AUTOSAR XML (schema 4-0-3)
package /ComponentTypes
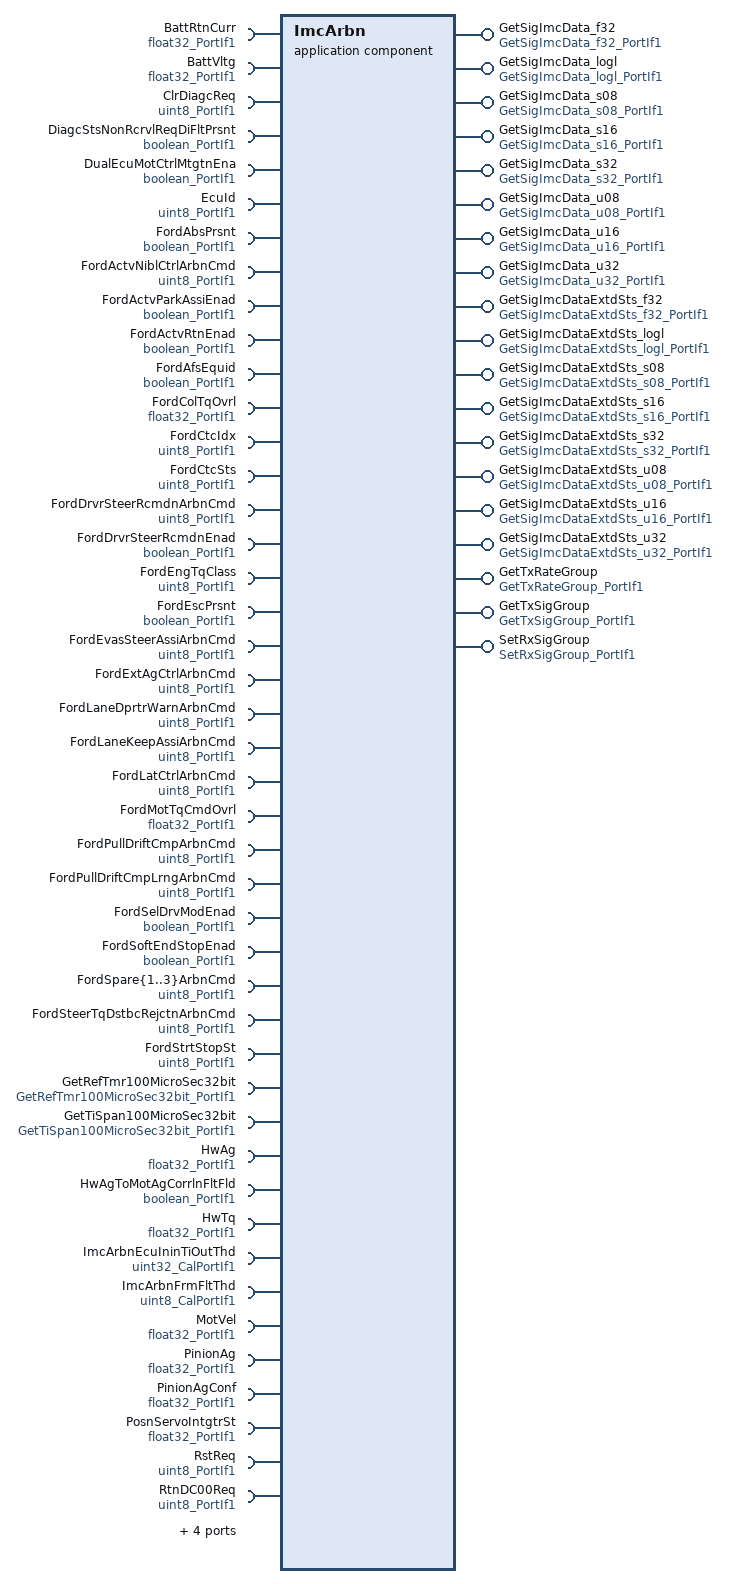
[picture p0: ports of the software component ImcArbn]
  application sw component type ImcArbn
    19 x provide port, all with server-com-spec{operation=Oper, queue-length=1}:
      GetSigImcData_f32: provided-interface=GetSigImcData_f32_PortIf1
      GetSigImcData_logl: provided-interface=GetSigImcData_logl_PortIf1
      GetSigImcData_s08: provided-interface=GetSigImcData_s08_PortIf1
      GetSigImcData_s16: provided-interface=GetSigImcData_s16_PortIf1
      GetSigImcData_s32: provided-interface=GetSigImcData_s32_PortIf1
      GetSigImcData_u08: provided-interface=GetSigImcData_u08_PortIf1
      GetSigImcData_u16: provided-interface=GetSigImcData_u16_PortIf1
      GetSigImcData_u32: provided-interface=GetSigImcData_u32_PortIf1
      GetSigImcDataExtdSts_f32: provided-interface=GetSigImcDataExtdSts_f32_PortIf1
      GetSigImcDataExtdSts_logl: provided-interface=GetSigImcDataExtdSts_logl_PortIf1
      GetSigImcDataExtdSts_s08: provided-interface=GetSigImcDataExtdSts_s08_PortIf1
      GetSigImcDataExtdSts_s16: provided-interface=GetSigImcDataExtdSts_s16_PortIf1
      GetSigImcDataExtdSts_s32: provided-interface=GetSigImcDataExtdSts_s32_PortIf1
      GetSigImcDataExtdSts_u08: provided-interface=GetSigImcDataExtdSts_u08_PortIf1
      GetSigImcDataExtdSts_u16: provided-interface=GetSigImcDataExtdSts_u16_PortIf1
      GetSigImcDataExtdSts_u32: provided-interface=GetSigImcDataExtdSts_u32_PortIf1
      GetTxRateGroup: provided-interface=GetTxRateGroup_PortIf1
      GetTxSigGroup: provided-interface=GetTxSigGroup_PortIf1
      SetRxSigGroup: provided-interface=SetRxSigGroup_PortIf1
    50 x require port:
      BattRtnCurr: nonqueued-receiver-com-spec{data-element=Val, filter=data-filter-type=ALWAYS}, required-interface=float32_PortIf1
      BattVltg: nonqueued-receiver-com-spec{data-element=Val, filter=data-filter-type=ALWAYS, init-value=6}, required-interface=float32_PortIf1
      ClrDiagcReq: nonqueued-receiver-com-spec{data-element=Val, filter=data-filter-type=ALWAYS, init-value=0}, required-interface=uint8_PortIf1
      DiagcStsNonRcrvlReqDiFltPrsnt: nonqueued-receiver-com-spec{data-element=Logl, filter=data-filter-type=ALWAYS, init-value=0}, required-interface=boolean_PortIf1
      DualEcuMotCtrlMtgtnEna: nonqueued-receiver-com-spec{data-element=Logl, filter=data-filter-type=ALWAYS, init-value=0}, required-interface=boolean_PortIf1
      EcuId: nonqueued-receiver-com-spec{data-element=Val, filter=data-filter-type=ALWAYS, init-value=0}, required-interface=uint8_PortIf1
      FordAbsPrsnt: nonqueued-receiver-com-spec{data-element=Logl, filter=data-filter-type=ALWAYS, init-value=0}, required-interface=boolean_PortIf1
      FordActvNiblCtrlArbnCmd: nonqueued-receiver-com-spec{data-element=Val, filter=data-filter-type=ALWAYS, init-value=0}, required-interface=uint8_PortIf1
      FordActvParkAssiEnad: nonqueued-receiver-com-spec{data-element=Logl, filter=data-filter-type=ALWAYS, init-value=0}, required-interface=boolean_PortIf1
      FordActvRtnEnad: nonqueued-receiver-com-spec{data-element=Logl, filter=data-filter-type=ALWAYS, init-value=1}, required-interface=boolean_PortIf1
      FordAfsEquid: nonqueued-receiver-com-spec{data-element=Logl, filter=data-filter-type=ALWAYS, init-value=0}, required-interface=boolean_PortIf1
      FordColTqOvrl: nonqueued-receiver-com-spec{data-element=Val, filter=data-filter-type=ALWAYS, init-value=0}, required-interface=float32_PortIf1
      FordCtcIdx: nonqueued-receiver-com-spec{data-element=Val, filter=data-filter-type=ALWAYS, init-value=0}, required-interface=uint8_PortIf1
      FordCtcSts: nonqueued-receiver-com-spec{data-element=Val, filter=data-filter-type=ALWAYS, init-value=0}, required-interface=uint8_PortIf1
      FordDrvrSteerRcmdnArbnCmd: nonqueued-receiver-com-spec{data-element=Val, filter=data-filter-type=ALWAYS, init-value=0}, required-interface=uint8_PortIf1
      FordDrvrSteerRcmdnEnad: nonqueued-receiver-com-spec{data-element=Logl, filter=data-filter-type=ALWAYS, init-value=0}, required-interface=boolean_PortIf1
      FordEngTqClass: nonqueued-receiver-com-spec{data-element=Val, filter=data-filter-type=ALWAYS, init-value=2}, required-interface=uint8_PortIf1
      FordEscPrsnt: nonqueued-receiver-com-spec{data-element=Logl, filter=data-filter-type=ALWAYS, init-value=0}, required-interface=boolean_PortIf1
      FordEvasSteerAssiArbnCmd: nonqueued-receiver-com-spec{data-element=Val, filter=data-filter-type=ALWAYS, init-value=0}, required-interface=uint8_PortIf1
      FordExtAgCtrlArbnCmd: nonqueued-receiver-com-spec{data-element=Val, filter=data-filter-type=ALWAYS, init-value=0}, required-interface=uint8_PortIf1
      FordLaneDprtrWarnArbnCmd: nonqueued-receiver-com-spec{data-element=Val, filter=data-filter-type=ALWAYS, init-value=0}, required-interface=uint8_PortIf1
      FordLaneKeepAssiArbnCmd: nonqueued-receiver-com-spec{data-element=Val, filter=data-filter-type=ALWAYS, init-value=0}, required-interface=uint8_PortIf1
      FordLatCtrlArbnCmd: nonqueued-receiver-com-spec{data-element=Val, filter=data-filter-type=ALWAYS, init-value=0}, required-interface=uint8_PortIf1
      FordMotTqCmdOvrl: nonqueued-receiver-com-spec{data-element=Val, filter=data-filter-type=ALWAYS, init-value=0}, required-interface=float32_PortIf1
      FordPullDriftCmpArbnCmd: nonqueued-receiver-com-spec{data-element=Val, filter=data-filter-type=ALWAYS, init-value=0}, required-interface=uint8_PortIf1
      FordPullDriftCmpLrngArbnCmd: nonqueued-receiver-com-spec{data-element=Val, filter=data-filter-type=ALWAYS, init-value=0}, required-interface=uint8_PortIf1
      FordSelDrvModEnad: nonqueued-receiver-com-spec{data-element=Logl, filter=data-filter-type=ALWAYS, init-value=0}, required-interface=boolean_PortIf1
      FordSoftEndStopEnad: nonqueued-receiver-com-spec{data-element=Logl, filter=data-filter-type=ALWAYS, init-value=0}, required-interface=boolean_PortIf1
      FordSpare{1..3}ArbnCmd: nonqueued-receiver-com-spec{data-element=Val, filter=data-filter-type=ALWAYS, init-value=0}, required-interface=uint8_PortIf1
      FordSteerTqDstbcRejctnArbnCmd: nonqueued-receiver-com-spec{data-element=Val, filter=data-filter-type=ALWAYS, init-value=0}, required-interface=uint8_PortIf1
      FordStrtStopSt: nonqueued-receiver-com-spec{data-element=Val, filter=data-filter-type=ALWAYS, init-value=0}, required-interface=uint8_PortIf1
      GetRefTmr100MicroSec32bit: client-com-spec=Oper, required-interface=GetRefTmr100MicroSec32bit_PortIf1
      GetTiSpan100MicroSec32bit: client-com-spec=Oper, required-interface=GetTiSpan100MicroSec32bit_PortIf1
      HwAg: nonqueued-receiver-com-spec{data-element=Val, filter=data-filter-type=ALWAYS, init-value=0}, required-interface=float32_PortIf1
      HwAgToMotAgCorrlnFltFld: nonqueued-receiver-com-spec{data-element=Logl, filter=data-filter-type=ALWAYS, init-value=0}, required-interface=boolean_PortIf1
      HwTq: nonqueued-receiver-com-spec{data-element=Val, filter=data-filter-type=ALWAYS, init-value=0}, required-interface=float32_PortIf1
      ImcArbnEcuIninTiOutThd: parameter-require-com-spec{init-value=500, parameter=Val}, required-interface=uint32_CalPortIf1
      ImcArbnFrmFltThd: parameter-require-com-spec{init-value=10, parameter=Val}, required-interface=uint8_CalPortIf1
      MotVel: nonqueued-receiver-com-spec{data-element=Val, filter=data-filter-type=ALWAYS, init-value=0}, required-interface=float32_PortIf1
      PinionAg: nonqueued-receiver-com-spec{data-element=Val, filter=data-filter-type=ALWAYS, init-value=0}, required-interface=float32_PortIf1
      PinionAgConf: nonqueued-receiver-com-spec{data-element=Val, filter=data-filter-type=ALWAYS, init-value=0}, required-interface=float32_PortIf1
      PosnServoIntgtrSt: nonqueued-receiver-com-spec{data-element=Val, filter=data-filter-type=ALWAYS, init-value=0}, required-interface=float32_PortIf1
      RstReq: nonqueued-receiver-com-spec{data-element=Val, filter=data-filter-type=ALWAYS, init-value=0}, required-interface=uint8_PortIf1
      RtnDC00Req: nonqueued-receiver-com-spec{data-element=Val, filter=data-filter-type=ALWAYS, init-value=0}, required-interface=uint8_PortIf1
      SetNtcSts: client-com-spec=Oper, required-interface=SetNtcSts_PortIf1
      SysSt: nonqueued-receiver-com-spec{data-element=Val, filter=data-filter-type=ALWAYS, init-value=3}, required-interface=SysSt1
      VehSpd: nonqueued-receiver-com-spec{data-element=Val, filter=data-filter-type=ALWAYS, init-value=0}, required-interface=float32_PortIf1
      VehSpdVld: nonqueued-receiver-com-spec{data-element=Logl, filter=data-filter-type=ALWAYS, init-value=0}, required-interface=boolean_PortIf1
    behavior ImcArbn_InternalBehavior
      exclusive area ExclsvAr1DrvrTxRxBuf
      exclusive area ExclsvAr2SigDataBuf
      ar-typed-per-instance-memorys:
        22 x data, all with sw-calibration-access=READ-ONLY:
          FrmFltCntr100MilliSec: type=Ary2D_u8_2_2
          FrmFltCntr10MilliSec: type=Ary2D_u8_2_2
          FrmFltCntr2MilliSec: type=Ary2D_u8_2_2
          ImcEcuComStrtTiRef: type=uint32
          PrevRollgCntrRxd: type=Ary1D_u8_ImcArbnB
          PrimSrcResyncCntr: type=Ary1D_u8_ImcArbnB
          PrimSrcRollgCntrResync: type=Ary1D_u8_ImcArbnB
          PrimSrcRxBuf: type=Ary2D_u8_ImcArbnA
          ResyncOnPrimActv: type=Ary1D_logl_ImcArbnA
          ResyncOnSecdryActv: type=Ary1D_logl_ImcArbnA
          RollgCntr: type=Ary1D_u8_3
          RxdSigData: type=Ary1D_u32_ImcArbnA
          RxdSigDataExtdSts: type=Ary1D_ImrArbnRxExtdSts2_ImcArbnA
          RxdSigDataSrc: type=Ary1D_ImcArbnRxDataSrc2_ImcArbnB
          SecdrySrcResyncCntr: type=Ary1D_u8_ImcArbnB
          SecdrySrcRollgCntrResync: type=Ary1D_u8_ImcArbnB
          SecdrySrcRxBuf: type=Ary2D_u8_ImcArbnA
          SigGroupDataSrc: type=Ary1D_ImcArbnRxDataSrc2_ImcArbnA
          SigGroupMissCntr: type=Ary1D_u8_ImcArbnB
          SigGroupNeverRxd: type=Ary1D_logl_ImcArbnA
          SigGroupSkipCntr: type=Ary1D_u8_ImcArbnB
          TxBuf: type=Ary2D_u8_ImcArbnA
      18 x operation invoked event:
        OIT_GetSigImcData_f32_Oper_GetSigImcData_f32_Oper: start-on-event=GetSigImcData_f32_Oper, operation=GetSigImcData_f32.Oper
        OIT_GetSigImcData_logl_Oper_GetSigImcData_logl_Oper: start-on-event=GetSigImcData_logl_Oper, operation=GetSigImcData_logl.Oper
        OIT_GetSigImcData_s08_Oper_GetSigImcData_s08_Oper: start-on-event=GetSigImcData_s08_Oper, operation=GetSigImcData_s08.Oper
        OIT_GetSigImcData_s16_Oper_GetSigImcData_s16_Oper: start-on-event=GetSigImcData_s16_Oper, operation=GetSigImcData_s16.Oper
        OIT_GetSigImcData_s32_Oper_GetSigImcData_s32_Oper: start-on-event=GetSigImcData_s32_Oper, operation=GetSigImcData_s32.Oper
        OIT_GetSigImcData_u08_Oper_GetSigImcData_u08_Oper: start-on-event=GetSigImcData_u08_Oper, operation=GetSigImcData_u08.Oper
        OIT_GetSigImcData_u16_Oper_GetSigImcData_u16_Oper: start-on-event=GetSigImcData_u16_Oper, operation=GetSigImcData_u16.Oper
        OIT_GetSigImcData_u32_Oper_GetSigImcData_u32_Oper: start-on-event=GetSigImcData_u32_Oper, operation=GetSigImcData_u32.Oper
        OIT_GetSigImcDataExtdSts_f32_Oper_GetSigImcDataExtdSts_f32_Oper: start-on-event=GetSigImcDataExtdSts_f32_Oper, operation=GetSigImcDataExtdSts_f32.Oper
        OIT_GetSigImcDataExtdSts_logl_Oper_GetSigImcDataExtdSts_logl_Oper: start-on-event=GetSigImcDataExtdSts_logl_Oper, operation=GetSigImcDataExtdSts_logl.Oper
        OIT_GetSigImcDataExtdSts_s08_Oper_GetSigImcDataExtdSts_s08_Oper: start-on-event=GetSigImcDataExtdSts_s08_Oper, operation=GetSigImcDataExtdSts_s08.Oper
        OIT_GetSigImcDataExtdSts_s16_Oper_GetSigImcDataExtdSts_s16_Oper: start-on-event=GetSigImcDataExtdSts_s16_Oper, operation=GetSigImcDataExtdSts_s16.Oper
        OIT_GetSigImcDataExtdSts_s32_Oper_GetSigImcDataExtdSts_s32_Oper: start-on-event=GetSigImcDataExtdSts_s32_Oper, operation=GetSigImcDataExtdSts_s32.Oper
        OIT_GetSigImcDataExtdSts_u08_Oper_GetSigImcDataExtdSts_u08_Oper: start-on-event=GetSigImcDataExtdSts_u08_Oper, operation=GetSigImcDataExtdSts_u08.Oper
        OIT_GetSigImcDataExtdSts_u16_Oper_GetSigImcDataExtdSts_u16_Oper: start-on-event=GetSigImcDataExtdSts_u16_Oper, operation=GetSigImcDataExtdSts_u16.Oper
        OIT_GetSigImcDataExtdSts_u32_Oper_GetSigImcDataExtdSts_u32_Oper: start-on-event=GetSigImcDataExtdSts_u32_Oper, operation=GetSigImcDataExtdSts_u32.Oper
        OIT_GetTxRateGroup_Oper_GetTxRateGroup_Oper: start-on-event=GetTxRateGroup_Oper, operation=GetTxRateGroup.Oper
        OIT_GetTxSigGroup_Oper_GetTxSigGroup_Oper: start-on-event=GetTxSigGroup_Oper, operation=GetTxSigGroup.Oper
      7 x timing event:
        ImcArbn_InitEvent: start-on-event=ImcArbnInit1, period=0
        TMT_ImcArbrPer1: start-on-event=ImcArbnPer1, period=0.002
        TMT_ImcArbrPer2: start-on-event=ImcArbnPer2, period=0.01
        TMT_ImcArbrPer3: start-on-event=ImcArbnPer3, period=0.1
        TMT_ImcArbrPer4: start-on-event=ImcArbnPer4, period=0.002
        TMT_ImcArbrPer5: start-on-event=ImcArbnPer5, period=0.01
        TMT_ImcArbrPer6: start-on-event=ImcArbnPer6, period=0.1
      operation invoked event OIT_SetRxSigGroup_Oper_SetRxSigGroup_Oper: start-on-event=SetRxSigGroup_Oper, operation=SetRxSigGroup.Oper
      explicit-inter-runnable-variables:
        data IniTiOutChkCmpl: type=boolean, init-value=0
      port-api-options:
        enable-take-address=false, indirect-api=false, port=BattRtnCurr
        enable-take-address=false, indirect-api=false, port=BattVltg
        enable-take-address=false, indirect-api=false, port=ClrDiagcReq
        enable-take-address=false, indirect-api=false, port=DiagcStsNonRcrvlReqDiFltPrsnt
        enable-take-address=false, indirect-api=false, port=DualEcuMotCtrlMtgtnEna
        enable-take-address=false, indirect-api=false, port=EcuId
        enable-take-address=false, indirect-api=false, port=FordAbsPrsnt
        enable-take-address=false, indirect-api=false, port=FordActvNiblCtrlArbnCmd
        enable-take-address=false, indirect-api=false, port=FordActvParkAssiEnad
        enable-take-address=false, indirect-api=false, port=FordActvRtnEnad
        enable-take-address=false, indirect-api=false, port=FordAfsEquid
        enable-take-address=false, indirect-api=false, port=FordColTqOvrl
        enable-take-address=false, indirect-api=false, port=FordCtcIdx
        enable-take-address=false, indirect-api=false, port=FordCtcSts
        enable-take-address=false, indirect-api=false, port=FordDrvrSteerRcmdnArbnCmd
        enable-take-address=false, indirect-api=false, port=FordDrvrSteerRcmdnEnad
        enable-take-address=false, indirect-api=false, port=FordEngTqClass
        enable-take-address=false, indirect-api=false, port=FordEscPrsnt
        enable-take-address=false, indirect-api=false, port=FordEvasSteerAssiArbnCmd
        enable-take-address=false, indirect-api=false, port=FordExtAgCtrlArbnCmd
        enable-take-address=false, indirect-api=false, port=FordLaneDprtrWarnArbnCmd
        enable-take-address=false, indirect-api=false, port=FordLaneKeepAssiArbnCmd
        enable-take-address=false, indirect-api=false, port=FordLatCtrlArbnCmd
        enable-take-address=false, indirect-api=false, port=FordMotTqCmdOvrl
        enable-take-address=false, indirect-api=false, port=FordPullDriftCmpArbnCmd
        enable-take-address=false, indirect-api=false, port=FordPullDriftCmpLrngArbnCmd
        enable-take-address=false, indirect-api=false, port=FordSelDrvModEnad
        enable-take-address=false, indirect-api=false, port=FordSoftEndStopEnad
        enable-take-address=false, indirect-api=false, port=FordSpare{1..3}ArbnCmd
        enable-take-address=false, indirect-api=false, port=FordSteerTqDstbcRejctnArbnCmd
        enable-take-address=false, indirect-api=false, port=FordStrtStopSt
        enable-take-address=false, indirect-api=false, port=GetRefTmr100MicroSec32bit
        enable-take-address=false, indirect-api=false, port=GetSigImcData_f32
        enable-take-address=false, indirect-api=false, port=GetSigImcData_logl
        enable-take-address=false, indirect-api=false, port=GetSigImcData_s08
        enable-take-address=false, indirect-api=false, port=GetSigImcData_s16
        enable-take-address=false, indirect-api=false, port=GetSigImcData_s32
        enable-take-address=false, indirect-api=false, port=GetSigImcData_u08
        enable-take-address=false, indirect-api=false, port=GetSigImcData_u16
        enable-take-address=false, indirect-api=false, port=GetSigImcData_u32
        enable-take-address=false, indirect-api=false, port=GetSigImcDataExtdSts_f32
        enable-take-address=false, indirect-api=false, port=GetSigImcDataExtdSts_logl
        enable-take-address=false, indirect-api=false, port=GetSigImcDataExtdSts_s08
        enable-take-address=false, indirect-api=false, port=GetSigImcDataExtdSts_s16
        enable-take-address=false, indirect-api=false, port=GetSigImcDataExtdSts_s32
        enable-take-address=false, indirect-api=false, port=GetSigImcDataExtdSts_u08
        enable-take-address=false, indirect-api=false, port=GetSigImcDataExtdSts_u16
        enable-take-address=false, indirect-api=false, port=GetSigImcDataExtdSts_u32
        enable-take-address=false, indirect-api=false, port=GetTiSpan100MicroSec32bit
        enable-take-address=false, indirect-api=false, port=GetTxRateGroup
        enable-take-address=false, indirect-api=false, port=GetTxSigGroup
        enable-take-address=false, indirect-api=false, port=HwAg
        enable-take-address=false, indirect-api=false, port=HwAgToMotAgCorrlnFltFld
        enable-take-address=false, indirect-api=false, port=HwTq
        enable-take-address=false, indirect-api=false, port=ImcArbnEcuIninTiOutThd
        enable-take-address=false, indirect-api=false, port=ImcArbnFrmFltThd
        enable-take-address=false, indirect-api=false, port=MotVel
        enable-take-address=false, indirect-api=false, port=PinionAg
        enable-take-address=false, indirect-api=false, port=PinionAgConf
        enable-take-address=false, indirect-api=false, port=PosnServoIntgtrSt
        enable-take-address=false, indirect-api=false, port=RstReq
        enable-take-address=false, indirect-api=false, port=RtnDC00Req
        enable-take-address=false, indirect-api=false, port=SetNtcSts
        enable-take-address=false, indirect-api=false, port=SetRxSigGroup
        enable-take-address=false, indirect-api=false, port=SysSt
        enable-take-address=false, indirect-api=false, port=VehSpd
        enable-take-address=false, indirect-api=false, port=VehSpdVld
      26 x runnable:
        GetSigImcData_f32_Oper: can-enter-exclusive-area=ExclsvAr2SigDataBuf, can-be-invoked-concurrently=true
        GetSigImcData_logl_Oper: can-enter-exclusive-area=ExclsvAr2SigDataBuf, can-be-invoked-concurrently=true
        GetSigImcData_s08_Oper: can-enter-exclusive-area=ExclsvAr2SigDataBuf, can-be-invoked-concurrently=true
        GetSigImcData_s16_Oper: can-enter-exclusive-area=ExclsvAr2SigDataBuf, can-be-invoked-concurrently=true
        GetSigImcData_s32_Oper: can-enter-exclusive-area=ExclsvAr2SigDataBuf, can-be-invoked-concurrently=true
        GetSigImcData_u08_Oper: can-enter-exclusive-area=ExclsvAr2SigDataBuf, can-be-invoked-concurrently=true
        GetSigImcData_u16_Oper: can-enter-exclusive-area=ExclsvAr2SigDataBuf, can-be-invoked-concurrently=true
        GetSigImcData_u32_Oper: can-enter-exclusive-area=ExclsvAr2SigDataBuf, can-be-invoked-concurrently=true
        GetSigImcDataExtdSts_f32_Oper: can-enter-exclusive-area=ExclsvAr2SigDataBuf, can-be-invoked-concurrently=true
        GetSigImcDataExtdSts_logl_Oper: can-enter-exclusive-area=ExclsvAr2SigDataBuf, can-be-invoked-concurrently=true
        GetSigImcDataExtdSts_s08_Oper: can-enter-exclusive-area=ExclsvAr2SigDataBuf, can-be-invoked-concurrently=true
        GetSigImcDataExtdSts_s16_Oper: can-enter-exclusive-area=ExclsvAr2SigDataBuf, can-be-invoked-concurrently=true
        GetSigImcDataExtdSts_s32_Oper: can-enter-exclusive-area=ExclsvAr2SigDataBuf, can-be-invoked-concurrently=true
        GetSigImcDataExtdSts_u08_Oper: can-enter-exclusive-area=ExclsvAr2SigDataBuf, can-be-invoked-concurrently=true
        GetSigImcDataExtdSts_u16_Oper: can-enter-exclusive-area=ExclsvAr2SigDataBuf, can-be-invoked-concurrently=true
        GetSigImcDataExtdSts_u32_Oper: can-enter-exclusive-area=ExclsvAr2SigDataBuf, can-be-invoked-concurrently=true
        GetTxRateGroup_Oper: can-enter-exclusive-area=ExclsvAr1DrvrTxRxBuf, can-be-invoked-concurrently=true
        GetTxSigGroup_Oper: can-enter-exclusive-area=ExclsvAr1DrvrTxRxBuf, can-be-invoked-concurrently=true
        ImcArbnInit1
          sync call SC_GetRefTmr100MicroSec32bit_Oper: operation=GetRefTmr100MicroSec32bit.Oper, timeout=0
        ImcArbnPer1: can-enter-exclusive-area=ExclsvAr1DrvrTxRxBuf
        ImcArbnPer2: can-enter-exclusive-area=ExclsvAr1DrvrTxRxBuf
          data-receive-point-by-arguments:
            33 x access:
              REC_BattRtnCurr_Val: accessed-variable=BattRtnCurr.Val
              REC_BattVltg_Val: accessed-variable=BattVltg.Val
              REC_ClrDiagcReq_Val: accessed-variable=ClrDiagcReq.Val
              REC_DiagcStsNonRcrvlReqDiFltPrsnt_Logl: accessed-variable=DiagcStsNonRcrvlReqDiFltPrsnt.Logl
              REC_DualEcuMotCtrlMtgtnEna_Logl: accessed-variable=DualEcuMotCtrlMtgtnEna.Logl
              REC_EcuId_Val: accessed-variable=EcuId.Val
              REC_FordActvNiblCtrlArbnCmd_Val: accessed-variable=FordActvNiblCtrlArbnCmd.Val
              REC_FordColTqOvrl_Val: accessed-variable=FordColTqOvrl.Val
              REC_FordDrvrSteerRcmdnArbnCmd_Val: accessed-variable=FordDrvrSteerRcmdnArbnCmd.Val
              REC_FordEvasSteerAssiArbnCmd_Val: accessed-variable=FordEvasSteerAssiArbnCmd.Val
              REC_FordExtAgCtrlArbnCmd_Val: accessed-variable=FordExtAgCtrlArbnCmd.Val
              REC_FordLaneDprtrWarnArbnCmd_Val: accessed-variable=FordLaneDprtrWarnArbnCmd.Val
              REC_FordLaneKeepAssiArbnCmd_Val: accessed-variable=FordLaneKeepAssiArbnCmd.Val
              REC_FordLatCtrlArbnCmd_Val: accessed-variable=FordLatCtrlArbnCmd.Val
              REC_FordMotTqCmdOvrl_Val: accessed-variable=FordMotTqCmdOvrl.Val
              REC_FordPullDriftCmpArbnCmd_Val: accessed-variable=FordPullDriftCmpArbnCmd.Val
              REC_FordPullDriftCmpLrngArbnCmd_Val: accessed-variable=FordPullDriftCmpLrngArbnCmd.Val
              REC_FordSpare{1..3}ArbnCmd_Val: accessed-variable=FordSpare{1..3}ArbnCmd.Val
              REC_FordSteerTqDstbcRejctnArbnCmd_Val: accessed-variable=FordSteerTqDstbcRejctnArbnCmd.Val
              REC_HwAg_Val: accessed-variable=HwAg.Val
              REC_HwAgToMotAgCorrlnFltFld_Logl: accessed-variable=HwAgToMotAgCorrlnFltFld.Logl
              REC_HwTq_Val: accessed-variable=HwTq.Val
              REC_MotVel_Val: accessed-variable=MotVel.Val
              REC_PinionAg_Val: accessed-variable=PinionAg.Val
              REC_PinionAgConf_Val: accessed-variable=PinionAgConf.Val
              REC_PosnServoIntgtrSt_Val: accessed-variable=PosnServoIntgtrSt.Val
              REC_RstReq_Val: accessed-variable=RstReq.Val
              REC_RtnDC00Req_Val: accessed-variable=RtnDC00Req.Val
              REC_SysSt_Val: accessed-variable=SysSt.Val
              REC_VehSpd_Val: accessed-variable=VehSpd.Val
              REC_VehSpdVld_Logl: accessed-variable=VehSpdVld.Logl
        ImcArbnPer3: can-enter-exclusive-area=ExclsvAr1DrvrTxRxBuf
          data-receive-point-by-arguments:
            13 x access:
              REC_FordAbsPrsnt_Logl: accessed-variable=FordAbsPrsnt.Logl
              REC_FordActvParkAssiEnad_Logl: accessed-variable=FordActvParkAssiEnad.Logl
              REC_FordActvRtnEnad_Logl: accessed-variable=FordActvRtnEnad.Logl
              REC_FordAfsEquid_Logl: accessed-variable=FordAfsEquid.Logl
              REC_FordCtcIdx_Val: accessed-variable=FordCtcIdx.Val
              REC_FordCtcSts_Val: accessed-variable=FordCtcSts.Val
              REC_FordDrvrSteerRecomEnad_Logl: accessed-variable=FordDrvrSteerRcmdnEnad.Logl
              REC_FordEngTqClass_Val: accessed-variable=FordEngTqClass.Val
              REC_FordEscPrsnt_Logl: accessed-variable=FordEscPrsnt.Logl
              REC_FordSelDrvModEnad_Logl: accessed-variable=FordSelDrvModEnad.Logl
              REC_FordSoftEndStopEnad_Logl: accessed-variable=FordSoftEndStopEnad.Logl
              REC_FordStrtStopSt_Val: accessed-variable=FordStrtStopSt.Val
              REC_VehSpd_Val: accessed-variable=VehSpd.Val
        ImcArbnPer4: can-enter-exclusive-area=[ExclsvAr1DrvrTxRxBuf, ExclsvAr2SigDataBuf]
          read-local-variables:
            access READ_IniTiOutChkCmpl: accessed-variable=IniTiOutChkCmpl
        ImcArbnPer5: can-enter-exclusive-area=[ExclsvAr1DrvrTxRxBuf, ExclsvAr2SigDataBuf]
          read-local-variables:
            access READ_IniTiOutChkCmpl: accessed-variable=IniTiOutChkCmpl
        ImcArbnPer6: can-enter-exclusive-area=[ExclsvAr1DrvrTxRxBuf, ExclsvAr2SigDataBuf]
          read-local-variables:
            access READ_IniTiOutChkCmpl: accessed-variable=IniTiOutChkCmpl
          sync call SC_GetRefTmr100MicroSec32bit_Oper: operation=GetRefTmr100MicroSec32bit.Oper, timeout=0
          sync call SC_GetTiSpan100MicroSec32bit_Oper: operation=GetTiSpan100MicroSec32bit.Oper, timeout=0
          sync call SC_SetNtcSts_Oper: operation=SetNtcSts.Oper, timeout=0
          written-local-variables:
            access WRITE_IniTiOutChkCmpl: accessed-variable=IniTiOutChkCmpl
        SetRxSigGroup_Oper: can-enter-exclusive-area=ExclsvAr1DrvrTxRxBuf
  swc implementation ImcArbn_Implementation: behavior=ImcArbn_InternalBehavior
    code-descriptors:
      code Default: artifact-descriptors=autosar-engineering-object={short-label=Default, category=SWSRC}
